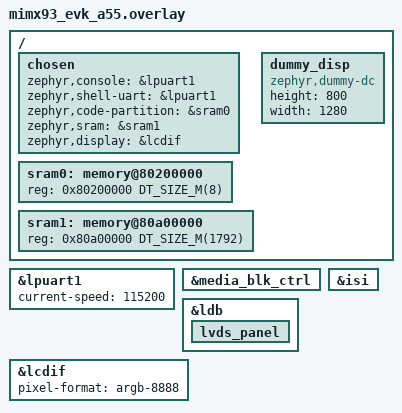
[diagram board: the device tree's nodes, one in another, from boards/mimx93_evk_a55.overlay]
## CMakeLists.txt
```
# Copyright 2024, NXP
# SPDX-License-Identifier: Apache-2.0

cmake_minimum_required(VERSION 3.20.0)

set(SHIELD nxp_x_rpi_cam_int)
find_package(Zephyr REQUIRED HINTS $ENV{ZEPHYR_BASE})

project(barcode_scanner)

# include directories for headers
set (ZXING_HEADERS_DIR
  "src/zxing-cpp/core/src"
#  "src/zxing-cpp/core/src/oned"
#  "src/zxing-cpp/core/src/qrcode"
)

# build readers
#  set (ZXING_HEADERS_DIR ${ZXING_HEADERS_DIR}
#      src/zxing-cpp/core/src/qrcode/
#  )

# build writers
#  set (ZXING_HEADERS_DIR ${ZXING_HEADERS_DIR}
#      src/zxing-cpp/core/src/BitMatrix.h
#      src/zxing-cpp/core/src/BitMatrixIO.h
#      src/zxing-cpp/core/src/Matrix.h
#      src/zxing-cpp/core/src/MultiFormatWriter.h
#      src/zxing-cpp/core/src/Range.h
#  )

# end of public header set

set (ZXING_SOURCES
  # base
  "src/zxing-cpp/core/src/BarcodeFormat.cpp"
  "src/zxing-cpp/core/src/BitArray.cpp"
  "src/zxing-cpp/core/src/BitMatrix.cpp"
  "src/zxing-cpp/core/src/BitMatrixIO.cpp"
  "src/zxing-cpp/core/src/CharacterSet.cpp"
  "src/zxing-cpp/core/src/ConcentricFinder.cpp"
  "src/zxing-cpp/core/src/ECI.cpp"
  "src/zxing-cpp/core/src/GenericGF.cpp"
  "src/zxing-cpp/core/src/GenericGFPoly.cpp"
  "src/zxing-cpp/core/src/GTIN.cpp"
  "src/zxing-cpp/core/src/Utf.cpp"
  "src/zxing-cpp/core/src/ZXBigInteger.cpp"

  #libzueci
  "src/zxing-cpp/core/src/libzueci/zueci.c"

  #aztec common
  # no such files

  # datamatrix common
  "src/zxing-cpp/core/src/datamatrix/DMBitLayout.cpp"
  "src/zxing-cpp/core/src/datamatrix/DMVersion.cpp"

  #oned commmon
  "src/zxing-cpp/core/src/oned/ODUPCEANCommon.cpp"
  "src/zxing-cpp/core/src/oned/ODCode128Patterns.cpp"

  #qr-code common
  "src/zxing-cpp/core/src/qrcode/QRCodecMode.cpp"
  "src/zxing-cpp/core/src/qrcode/QRErrorCorrectionLevel.cpp"
  "src/zxing-cpp/core/src/qrcode/QRVersion.cpp"
)
#zephyr_linker_sources(SECTIONS linker_chre.ld)

# build readers
  zephyr_compile_definitions(ZXING_BUILD_READERS)
  set (ZXING_SOURCES ${ZXING_SOURCES}
    #reader
    "src/zxing-cpp/core/src/BinaryBitmap.cpp"
    "src/zxing-cpp/core/src/BitSource.cpp"
    "src/zxing-cpp/core/src/Content.cpp"
    "src/zxing-cpp/core/src/DecodeHints.cpp"
    "src/zxing-cpp/core/src/GlobalHistogramBinarizer.cpp"
    "src/zxing-cpp/core/src/GridSampler.cpp"
    "src/zxing-cpp/core/src/HRI.cpp"
    "src/zxing-cpp/core/src/HybridBinarizer.cpp"
    "src/zxing-cpp/core/src/MultiFormatReader.cpp"
    "src/zxing-cpp/core/src/PerspectiveTransform.cpp"
    "src/zxing-cpp/core/src/ReadBarcode.cpp"
    "src/zxing-cpp/core/src/ReedSolomonDecoder.cpp"
    "src/zxing-cpp/core/src/Result.cpp"
    "src/zxing-cpp/core/src/ResultPoint.cpp"
    "src/zxing-cpp/core/src/TextDecoder.cpp"
    "src/zxing-cpp/core/src/WhiteRectDetector.cpp"

    #aztec reader
    "src/zxing-cpp/core/src/aztec/AZDecoder.cpp"
    "src/zxing-cpp/core/src/aztec/AZDetector.cpp"
    "src/zxing-cpp/core/src/aztec/AZReader.cpp"

    #datamatrix reader
    "src/zxing-cpp/core/src/datamatrix/DMDataBlock.cpp"
    "src/zxing-cpp/core/src/datamatrix/DMDecoder.cpp"
    "src/zxing-cpp/core/src/datamatrix/DMDetector.cpp"
    "src/zxing-cpp/core/src/datamatrix/DMReader.cpp"

    #maxicode reader
    "src/zxing-cpp/core/src/maxicode/MCBitMatrixParser.cpp"
    "src/zxing-cpp/core/src/maxicode/MCDecoder.cpp"
    "src/zxing-cpp/core/src/maxicode/MCReader.cpp"

    #oned reader
    "src/zxing-cpp/core/src/oned/ODCodabarReader.cpp"
    "src/zxing-cpp/core/src/oned/ODCode39Reader.cpp"
    "src/zxing-cpp/core/src/oned/ODCode93Reader.cpp"
    "src/zxing-cpp/core/src/oned/ODCode128Reader.cpp"
    "src/zxing-cpp/core/src/oned/ODDataBarCommon.cpp"
    "src/zxing-cpp/core/src/oned/ODDataBarReader.cpp"
    "src/zxing-cpp/core/src/oned/ODDataBarExpandedBitDecoder.cpp"
    "src/zxing-cpp/core/src/oned/ODDataBarExpandedReader.cpp"
    "src/zxing-cpp/core/src/oned/ODITFReader.cpp"
    "src/zxing-cpp/core/src/oned/ODMultiUPCEANReader.cpp"
    "src/zxing-cpp/core/src/oned/ODReader.cpp"
    "src/zxing-cpp/core/src/oned/ODRowReader.cpp"

    #pdf417 reader
    "src/zxing-cpp/core/src/pdf417/PDFBarcodeValue.cpp"
    "src/zxing-cpp/core/src/pdf417/PDFBoundingBox.cpp"
    "src/zxing-cpp/core/src/pdf417/PDFCodewordDecoder.cpp"
    "src/zxing-cpp/core/src/pdf417/PDFDecoder.cpp"
    "src/zxing-cpp/core/src/pdf417/PDFDetectionResult.cpp"
    "src/zxing-cpp/core/src/pdf417/PDFDetectionResultColumn.cpp"
    "src/zxing-cpp/core/src/pdf417/PDFDetector.cpp"
    "src/zxing-cpp/core/src/pdf417/PDFModulusGF.cpp"
    "src/zxing-cpp/core/src/pdf417/PDFModulusPoly.cpp"
    "src/zxing-cpp/core/src/pdf417/PDFReader.cpp"
    "src/zxing-cpp/core/src/pdf417/PDFScanningDecoder.cpp"

    #qr-code reader
    "src/zxing-cpp/core/src/qrcode/QRBitMatrixParser.cpp"
    "src/zxing-cpp/core/src/qrcode/QRDataBlock.cpp"
    "src/zxing-cpp/core/src/qrcode/QRDecoder.cpp"
    "src/zxing-cpp/core/src/qrcode/QRDetector.cpp"
    "src/zxing-cpp/core/src/qrcode/QRFormatInformation.cpp"
    "src/zxing-cpp/core/src/qrcode/QRReader.cpp"
  )

# build writers
#  zephyr_compile_definitions(ZXING_BUILD_WRITERS)
#  set (ZXING_SOURCES ${ZXING_SOURCES}
#    #writer
#    "src/zxing-cpp/core/src/ReedSolomonEncoder.cpp"
#    "src/zxing-cpp/core/src/TextEncoder.cpp"
#    "src/zxing-cpp/core/src/MultiFormatWriter.cpp"
#
#    # oned writer
#    "src/zxing-cpp/core/src/oned/ODCodabarWriter.cpp"
#    "src/zxing-cpp/core/src/oned/ODCode39Writer.cpp"
#    "src/zxing-cpp/core/src/oned/ODCode93Writer.cpp"
#    "src/zxing-cpp/core/src/oned/ODCode128Writer.cpp"
#    "src/zxing-cpp/core/src/oned/ODEAN8Writer.cpp"
#    "src/zxing-cpp/core/src/oned/ODEAN13Writer.cpp"
#    "src/zxing-cpp/core/src/oned/ODITFWriter.cpp"
#    "src/zxing-cpp/core/src/oned/ODUPCEWriter.cpp"
#    "src/zxing-cpp/core/src/oned/ODUPCAWriter.cpp"
#    "src/zxing-cpp/core/src/oned/ODWriterHelper.cpp"
#
#    #qr-code writer
#    "src/zxing-cpp/core/src/qrcode/QREncoder.cpp"
#    "src/zxing-cpp/core/src/qrcode/QRMaskUtil.cpp"
#    "src/zxing-cpp/core/src/qrcode/QRMatrixUtil.cpp"
#    "src/zxing-cpp/core/src/qrcode/QRWriter.cpp"
#  )

target_include_directories(app PRIVATE
    ${ZXING_HEADERS_DIR}
    src/generated
    src/custom
    src/generated/guider_customer_fonts
    src/generated/guider_fonts
    src/generated/images
)

target_compile_definitions(app PRIVATE Zxing_EXPORTS)

FILE(GLOB gui_guider_sources src/*.c src/generated/*.c src/custom/*.c src/generated/guider_customer_fonts/*.c src/generated/guider_fonts/*.c src/generated/images/*.c)

target_sources(app PRIVATE
    ${ZXING_SOURCES}
    ${gui_guider_sources}
    src/main.cpp
    src/zx_scan.cpp
)

target_compile_definitions(app PRIVATE LV_LVGL_H_INCLUDE_SIMPLE)
```

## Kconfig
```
# Copyright 2024, NXP
# SPDX-License-Identifier: Apache-2.0

menu "Barcode scanner demo"

config BARCODE_TIME_MEASUREMENT
	bool "measure main thread execution time"
	default n
	help
	  measure main thread execution time

config BARCODE_VIDEO_FRAME_CHECK
	bool "check for empty video frame"
	default n
	help
	  check for empty video frame

module = BARCODE_MAIN
module-str = barcode scanner main thread
source "subsys/logging/Kconfig.template.log_config"

module = BARCODE_ZXING
module-str = barcode scanner zxing thread
source "subsys/logging/Kconfig.template.log_config"

endmenu

source "Kconfig.zephyr"
```

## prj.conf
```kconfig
# Copyright 2024,2025 NXP
# SPDX-License-Identifier: Apache-2.0

## DEVICE ##
CONFIG_SERIAL=y
CONFIG_UART_INTERRUPT_DRIVEN=y
CONFIG_DISPLAY=y
CONFIG_VIDEO=y
CONFIG_VIDEO_BUFFER_POOL_NUM_MAX=5

## KERNEL ##
CONFIG_SPEED_OPTIMIZATIONS=y
CONFIG_SCHED_SCALABLE=y
CONFIG_WAITQ_SCALABLE=y
CONFIG_PICOLIBC=y
# CONFIG_PICOLIBC_USE_MODULE is not set
CONFIG_MAIN_STACK_SIZE=16384
CONFIG_SYSTEM_WORKQUEUE_STACK_SIZE=16384
#CONFIG_HEAP_MEM_POOL_SIZE=4194304
CONFIG_COMMON_LIBC_MALLOC_ARENA_SIZE=16777216

## SHELL ##
CONFIG_CONSOLE=y
CONFIG_UART_CONSOLE=y
CONFIG_LOG=y
CONFIG_LOG_RUNTIME_FILTERING=y
CONFIG_LOG_PRINTK=y
CONFIG_LOG_DEFAULT_LEVEL=2
CONFIG_LOG_SPEED=y
CONFIG_LOG_BLOCK_IN_THREAD=y
CONFIG_LOG_BLOCK_IN_THREAD_TIMEOUT_MS=16
CONFIG_LOG_BUFFER_SIZE=16384
CONFIG_SHELL=y
CONFIG_SHELL_PROMPT_UART="zephyr:~$ "
CONFIG_SHELL_BACKEND_SERIAL_LOG_MESSAGE_QUEUE_TIMEOUT=1000
CONFIG_SHELL_BACKEND_SERIAL_LOG_MESSAGE_QUEUE_SIZE=4096

## STATS ##
CONFIG_STATS=y
CONFIG_THREAD_RUNTIME_STATS=y
CONFIG_THREAD_RUNTIME_STATS_USE_TIMING_FUNCTIONS=y

## CPP ##
CONFIG_CPP=y
CONFIG_STD_CPP17=y
CONFIG_GLIBCXX_LIBCPP=y
CONFIG_CPP_EXCEPTIONS=y
CONFIG_CPP_RTTI=y

## LVGL ##
CONFIG_LV_Z_MEM_POOL_HEAP_LIB_C=y
CONFIG_LVGL=y
CONFIG_LV_Z_SHELL=y
CONFIG_LV_USE_LOG=y
CONFIG_LV_USE_KEYBOARD=n

## APP ##
CONFIG_BARCODE_TIME_MEASUREMENT=n
CONFIG_BARCODE_VIDEO_FRAME_CHECK=n
CONFIG_BARCODE_MAIN_LOG_LEVEL_WRN=y
CONFIG_BARCODE_ZXING_LOG_LEVEL_WRN=y
```

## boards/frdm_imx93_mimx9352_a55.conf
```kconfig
# Copyright 2024,2025 NXP
# SPDX-License-Identifier: Apache-2.0

## DEVICE ##
CONFIG_PINCTRL=y
CONFIG_PINCTRL_DYNAMIC=y
CONFIG_CLOCK_CONTROL=y
CONFIG_GPIO=y
CONFIG_GPIO_SHELL=y
CONFIG_PM_CPU_OPS=y
CONFIG_PSCI_SHELL=y
CONFIG_REGULATOR=y
CONFIG_REGULATOR_FIXED=y
CONFIG_I2C=y
CONFIG_I2C_CALLBACK=y
CONFIG_MFD_ADP5585_INIT_PRIORITY=55
CONFIG_GPIO_ADP5585_INIT_PRIORITY=56
CONFIG_GPIO_PCA_SERIES_INIT_PRIORITY=60
CONFIG_REGULATOR_FIXED_INIT_PRIORITY=75
CONFIG_VIDEO_MCUX_ISI_INIT_PRIORITY=90
CONFIG_DISPLAY_INIT_PRIORITY=85
CONFIG_VIDEO_INIT_PRIORITY=90

## STATS ##
CONFIG_I2C_STATS=y

## KERNEL ##
#CONFIG_XIP=y
#CONFIG_USE_DT_CODE_PARTITION=y
#CONFIG_KERNEL_VM_SIZE=0x80000000
#CONFIG_MAX_XLAT_TABLES=256
CONFIG_VIDEO_BUFFER_POOL_SZ_MAX=2097152

## LVGL ##
CONFIG_LV_COLOR_DEPTH_32=y
CONFIG_LV_Z_DOUBLE_VDB=y
CONFIG_LV_Z_VDB_SIZE=100
CONFIG_LV_Z_FULL_REFRESH=y
```

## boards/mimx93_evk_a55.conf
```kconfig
# Copyright 2024, NXP
# SPDX-License-Identifier: Apache-2.0

## DEVICE ##
CONFIG_PINCTRL=y
CONFIG_PINCTRL_DYNAMIC=y
CONFIG_CLOCK_CONTROL=y
CONFIG_GPIO=y
CONFIG_GPIO_SHELL=y
CONFIG_REGULATOR=y
CONFIG_REGULATOR_FIXED=y
CONFIG_SERIAL=y
CONFIG_UART_INTERRUPT_DRIVEN=y
CONFIG_I2C=y
CONFIG_I2C_CALLBACK=y
CONFIG_DISPLAY=y
CONFIG_VIDEO=y
CONFIG_VIDEO_BUFFER_POOL_SZ_MAX=8192000
CONFIG_VIDEO_BUFFER_POOL_NUM_MAX=5
CONFIG_GPIO_INIT_PRIORITY=10
CONFIG_I2C_INIT_PRIORITY=15
CONFIG_GPIO_ADP5585_GPIO_INIT_PRIORITY=20
CONFIG_GPIO_PCA953X_INIT_PRIORITY=21
CONFIG_GPIO_HOGS_INIT_PRIORITY=25
CONFIG_REGULATOR_FIXED_INIT_PRIORITY=30
CONFIG_VIDEO_MT9M114_INIT_PRIORITY=70
CONFIG_VIDEO_PARALLEL_CSI_INIT_PRIORITY=80
CONFIG_DISPLAY_INIT_PRIORITY=85
CONFIG_VIDEO_INIT_PRIORITY=90

## KERNEL ##
CONFIG_XIP=y
CONFIG_USE_DT_CODE_PARTITION=y

CONFIG_KERNEL_VM_SIZE=0x80000000
CONFIG_COMMON_LIBC_MALLOC_ARENA_SIZE=268435456

CONFIG_MAX_XLAT_TABLES=256
```

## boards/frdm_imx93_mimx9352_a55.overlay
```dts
/*
 * Copyright 2024,2025 NXP
 *
 * SPDX-License-Identifier: Apache-2.0
 */

/delete-node/ &dram;

/{
	chosen{
		zephyr,console = &lpuart1;
		zephyr,shell-uart = &lpuart1;
	};

	dram: memory@d0000000 {
		reg = <0xd0000000 DT_SIZE_M(512)>;
	};
};

&lpuart1 {
	current-speed = <115200>;
	status = "okay";
};
```

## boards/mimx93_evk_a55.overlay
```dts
/*
 * Copyright 2024, NXP
 *
 * SPDX-License-Identifier: Apache-2.0
 */

/delete-node/ &sram0;

/{
	chosen{
		zephyr,console = &lpuart1;
		zephyr,shell-uart = &lpuart1;
		zephyr,code-partition = &sram0;
		zephyr,sram = &sram1;
		zephyr,display = &lcdif;
	};

	sram0: memory@80200000 {
		reg = <0x80200000 DT_SIZE_M(8)>;
	};

	sram1: memory@80a00000 {
		reg = <0x80a00000 DT_SIZE_M(1792)>;
	};

	dummy_disp: dummy_disp {
		compatible = "zephyr,dummy-dc";
		height = <800>;
		width = <1280>;
		status = "okay";
	};
};

&lpuart1 {
	current-speed = <115200>;
};

&media_blk_ctrl {
	status = "okay";
};

&ldb {
	status = "okay";

	lvds_panel: lvds_panel {
		status = "okay";
	};
};

&lcdif {
	pixel-format = "argb-8888";
	status = "okay";
};

&isi {
	status = "okay";
};
```

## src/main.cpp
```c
/*
 * Copyright 2024,2025 NXP
 *
 * SPDX-License-Identifier: Apache-2.0
 */
/** ZephyrOS include group */
#include <zephyr/cache.h>
#include <zephyr/device.h>
#include <zephyr/drivers/display.h>
#include <zephyr/drivers/i2c.h>
#include <zephyr/drivers/video.h>
#include <zephyr/kernel.h>
#include <zephyr/sys/printk.h>
#include <zephyr/sys/util.h>

/** C STD include group */
#include <cinttypes>
#include <cstdio>
#include <cstring>

/** CPP STD/STL include group */
#include <vector>

/** GUI-Guider include group */
#include "../custom/custom.h"
#include "../generated/events_init.h"
#include "../generated/gui_guider.h"

/** Project include group */
#include "zx_scan.h"

/** Zephyr logging include group */
#include <zephyr/logging/log.h>
LOG_MODULE_REGISTER(main_tr, CONFIG_BARCODE_MAIN_LOG_LEVEL);

const struct device *video_dev = DEVICE_DT_GET(DT_CHOSEN(zephyr_camera));
struct video_buffer *my_video_buffer_pool[CONFIG_VIDEO_BUFFER_POOL_NUM_MAX];

const struct device *display_dev = DEVICE_DT_GET(DT_CHOSEN(zephyr_display));

K_THREAD_STACK_DEFINE(zx_scan_thread_stack, ZX_SCAN_THREAD_STACK_SIZE);
struct k_thread zx_scan_thread;
zx_scan_param_t zx_param =
{
    .prio_normal = ZX_SCAN_THREAD_NORMAL_PRIO,
    .width = 640,
    .height = 600,
};
zx_scan_t zx_scan;

lv_ui guider_ui;

lv_image_dsc_t img_preview_desc = {
    .header = {
        .magic = LV_IMAGE_HEADER_MAGIC,
        .cf = LV_COLOR_FORMAT_ARGB8888,
        .flags = 0,
        .w = 640,
        .h = 600,
        .stride = 640 * 4,
        .reserved_2 = 0,
    },
  .data_size = 640 * 600 * 4,
  .data = nullptr,
};

#ifdef CONFIG_BARCODE_TIME_MEASUREMENT
/** used by time measurement */
uint64_t stime, etime;
#endif // CONFIG_BARCODE_TIME_MEASUREMENT

int disp_dev_config(struct device const * const dev, struct display_buffer_descriptor *desc)
{
    struct display_capabilities capabilities;
    int ret = 0;

    if (!device_is_ready(dev)) {
        LOG_ERR("Display device %s not ready", dev->name);
        return -ENODEV;
    }

    LOG_INF("Configuring display: %s", dev->name);

    // Retrieve display capabilities
    display_get_capabilities(dev, &capabilities);

    LOG_INF("- Capabilities:");
    LOG_INF("  Resolution: %u x %u", capabilities.x_resolution, capabilities.y_resolution);
    LOG_INF("  Supported formats: 0x%08x, Current format: %u", 
            capabilities.supported_pixel_formats, capabilities.current_pixel_format);
    LOG_INF("  Current orientation: %u", capabilities.current_orientation);

    // Verify resolution support
    if (capabilities.x_resolution != 1024 || capabilities.y_resolution != 600) {
        LOG_ERR("Unsupported resolution: %u x %u (expected: 1024 x 600)", 
                capabilities.x_resolution, capabilities.y_resolution);
        return -EINVAL;
    }

    // Set pixel format to ARGB8888
    ret = display_set_pixel_format(dev, PIXEL_FORMAT_ARGB_8888);
    if (ret) {
        LOG_ERR("Failed to set pixel format");
        return ret;
    }

    // Define buffer dimensions (fixed for this display)
    const size_t rect_w = 1024;
    const size_t rect_h = 600;

    // Calculate buffer size and pitch
    const size_t buf_size = rect_w * rect_h * 4;  // 4 bytes per pixel (ARGB8888)
    const size_t pitch = rect_w * 4;

    LOG_INF("Buffer: %zu x %zu, size=%zu bytes, pitch=%zu bytes", 
            rect_w, rect_h, buf_size, pitch);

    // Populate descriptor
    desc->buf_size = buf_size;
    desc->pitch = pitch;
    desc->width = rect_w;
    desc->height = rect_h;

    return 0;
}

/**
 * @brief Configures the video device (camera) with desired format, frame rate, and capabilities.
 *
 * This function:
 * - Queries and logs input/output capabilities.
 * - Sets input (camera) format to UYVY (640x600).
 * - Sets output format to AR24 (640x600).
 * - Sets frame rate to 30 fps.
 * - Enumerates supported frame intervals.
 *
 * @param dev Pointer to the video device.
 * @param fmt Pointer to output format structure to be filled.
 * @return 0 on success, non-zero on failure.
 */
int video_dev_config(const struct device *const dev, struct video_format *const fmt)
{
    struct video_caps caps;
    struct video_format output_fmt;
#if CONFIG_DT_HAS_NXP_IMX_ISI_ENABLED
    struct video_format camera_fmt;
#endif // CONFIG_DT_HAS_NXP_IMX_ISI_ENABLED
    struct video_frmival frmival;
    struct video_frmival_enum fie;
    int i = 0;

    if (!device_is_ready(dev)) {
        LOG_ERR("Video device %s not ready", dev->name);
        return -ENODEV;
    }

#if CONFIG_DT_HAS_NXP_IMX_ISI_ENABLED
    /* Query input endpoint (camera) capabilities */
    if (video_get_caps(dev, VIDEO_EP_IN, &caps)) {
        LOG_ERR("Failed to retrieve input capabilities");
        return -EIO;
    }

    LOG_INF("- Input Capabilities:");
    while (caps.format_caps[i].pixelformat) {
        const struct video_format_cap *fcap = &caps.format_caps[i];
        LOG_INF("  %c%c%c%c | W[%u;%u;%u] | H[%u;%u;%u]",
               (char)fcap->pixelformat,
               (char)(fcap->pixelformat >> 8),
               (char)(fcap->pixelformat >> 16),
               (char)(fcap->pixelformat >> 24),
               fcap->width_min, fcap->width_max, fcap->width_step,
               fcap->height_min, fcap->height_max, fcap->height_step);
        i++;
    }
    i = 0;
#endif // CONFIG_DT_HAS_NXP_IMX_ISI_ENABLED

    /* Query output endpoint (processing) capabilities */
    if (video_get_caps(dev, VIDEO_EP_OUT, &caps)) {
        LOG_ERR("Failed to retrieve output capabilities");
        return -EIO;
    }

    LOG_INF("- Output Capabilities:");
    while (caps.format_caps[i].pixelformat) {
        const struct video_format_cap *fcap = &caps.format_caps[i];
        LOG_INF("  %c%c%c%c | W[%u;%u;%u] | H[%u;%u;%u]",
               (char)fcap->pixelformat,
               (char)(fcap->pixelformat >> 8),
               (char)(fcap->pixelformat >> 16),
               (char)(fcap->pixelformat >> 24),
               fcap->width_min, fcap->width_max, fcap->width_step,
               fcap->height_min, fcap->height_max, fcap->height_step);
        i++;
    }

#if CONFIG_DT_HAS_NXP_IMX_ISI_ENABLED
    /* Configure input (camera) format: UYVY, 640x600 */
    if (video_get_format(dev, VIDEO_EP_IN, &camera_fmt)) {
        LOG_ERR("Failed to retrieve default input format");
        return -EIO;
    }

    camera_fmt.pixelformat = VIDEO_FOURCC_FROM_STR("UYVY");
    camera_fmt.width = 640;
    camera_fmt.height = 600;
    camera_fmt.pitch = fmt->width * video_bits_per_pixel(fmt->pixelformat) / BITS_PER_BYTE;

    LOG_INF("- Input Format: %c%c%c%c @ %ux%u",
           (char)camera_fmt.pixelformat,
           (char)(camera_fmt.pixelformat >> 8),
           (char)(camera_fmt.pixelformat >> 16),
           (char)(camera_fmt.pixelformat >> 24),
           camera_fmt.width, camera_fmt.height);

    if (video_set_format(dev, VIDEO_EP_IN, &camera_fmt)) {
        LOG_ERR("Failed to set input format");
        return -EIO;
    }
#endif // CONFIG_DT_HAS_NXP_IMX_ISI_ENABLED

    /* Configure output format: AR24, 640x600 */
    if (video_get_format(dev, VIDEO_EP_OUT, &output_fmt)) {
        LOG_ERR("Failed to retrieve default output format");
        return -EIO;
    }

    output_fmt.pixelformat = VIDEO_FOURCC_FROM_STR("AR24");
    output_fmt.width = 640;
    output_fmt.height = 600;
    output_fmt.pitch = output_fmt.width * video_bits_per_pixel(output_fmt.pixelformat) / BITS_PER_BYTE;

    LOG_INF("- Output Format: %c%c%c%c @ %ux%u",
           (char)output_fmt.pixelformat,
           (char)(output_fmt.pixelformat >> 8),
           (char)(output_fmt.pixelformat >> 16),
           (char)(output_fmt.pixelformat >> 24),
           output_fmt.width, output_fmt.height);

    if (video_set_format(dev, VIDEO_EP_OUT, &output_fmt)) {
        LOG_ERR("Failed to set output format");
        return -EIO;
    }

    /* Copy final format to output */
    memcpy(fmt, &output_fmt, sizeof(struct video_format));

    /* Query and log default frame rate */
    if (!video_get_frmival(dev, VIDEO_EP_OUT, &frmival)) {
        LOG_INF("- Default frame rate: %.2f fps",
               1.0 * frmival.denominator / frmival.numerator);
    }

    /* List supported frame intervals for the output format */
    LOG_INF("- Supported frame intervals:");
    memset(&fie, 0, sizeof(fie));
#if CONFIG_DT_HAS_NXP_IMX_ISI_ENABLED
    fie.format = &camera_fmt;
#else // CONFIG_DT_HAS_NXP_IMX_ISI_ENABLED
    fie.format = &output_fmt;  // Fixed typo: 'outout_fmt' → 'output_fmt'
#endif // CONFIG_DT_HAS_NXP_IMX_ISI_ENABLED

    while (1) {
        int ret = video_enum_frmival(dev, VIDEO_EP_OUT, &fie);
        if (ret) {
            break;
        }

        LOG_INF("  Index %u: ret=%d", fie.index, ret);
        if (fie.type == VIDEO_FRMIVAL_TYPE_DISCRETE) {
            LOG_INF("    %u/%u", fie.discrete.numerator, fie.discrete.denominator);
        } else {
            LOG_INF("    [min=%u/%u; max=%u/%u; step=%u/%u]",
                   fie.stepwise.min.numerator, fie.stepwise.min.denominator,
                   fie.stepwise.max.numerator, fie.stepwise.max.denominator,
                   fie.stepwise.step.numerator, fie.stepwise.step.denominator);
        }
        fie.index++;
    }

    /* Set frame rate to 30 fps */
    frmival.numerator = 30;
    frmival.denominator = 1;

    if (!video_set_frmival(dev, VIDEO_EP_OUT, &frmival)) {
        LOG_INF("- Frame rate set to %.2f fps", 1.0 * frmival.denominator / frmival.numerator);
    } else {
        LOG_ERR("- Failed to set frame rate to %.2f fps", 1.0 * frmival.denominator / frmival.numerator);
        return -EIO;
    }

    LOG_INF("Video device configuration completed successfully");
    return 0;
}

/**
 * @brief Main application entry point.
 *
 * Initializes:
 * - Video and display devices
 * - Video buffer pool
 * - ZXing scan thread
 * - GUI
 * - Starts video stream
 * - Main loop: dequeue, process, display, enqueue
 */
int main(void)
{
    struct display_buffer_descriptor buf_desc;
    struct video_format fmt_desc;
    volatile bool zx_frame_copied = false;
    int frame_cnt = 0;
    struct video_buffer *vbuf = nullptr;

    // Set thread priority
    k_thread_priority_set(k_current_get(), 5);

    // Configure video device
    if (video_dev_config(video_dev, &fmt_desc) != 0) {
        LOG_ERR("Failed to configure video device");
        return -1;
    }

    int bsize = fmt_desc.pitch * fmt_desc.height;
    LOG_INF("Buffer size: %ld, Pool size: %ld", bsize, ARRAY_SIZE(my_video_buffer_pool));

    // Allocate and enqueue video buffers
    for (int i = 0; i < ARRAY_SIZE(my_video_buffer_pool); i++) {
        my_video_buffer_pool[i] = video_buffer_aligned_alloc(bsize, CONFIG_VIDEO_BUFFER_POOL_ALIGN, K_FOREVER);
        if (!my_video_buffer_pool[i]) {
            LOG_ERR("Failed to allocate video buffer %d", i);
            return -1;
        }

#ifdef CONFIG_BARCODE_VIDEO_FRAME_CHECK
        ((uint32_t*)my_video_buffer_pool[i]->buffer)[0] = 0x00f0f0f0;
#endif // CONFIG_BARCODE_VIDEO_FRAME_CHECK

        if (video_enqueue(video_dev, VIDEO_EP_OUT, my_video_buffer_pool[i])) {
            LOG_ERR("Failed to enqueue buffer %d", i);
            return -1;
        }

        LOG_INF("Buffer %d/%d: 0x%8.8p", i, ARRAY_SIZE(my_video_buffer_pool), (void*)my_video_buffer_pool[i]->buffer);
    }

    // Configure display
    if (disp_dev_config(display_dev, &buf_desc) != 0) {
        LOG_ERR("Failed to configure display");
        return -1;
    }

    // Start ZXing scan thread
    k_thread_create(&zx_scan_thread, zx_scan_thread_stack,
                    ZX_SCAN_THREAD_STACK_SIZE,
                    (k_thread_entry_t)ZX_ScanTask, (void*)&zx_scan, (void*)&zx_param, NULL,
                    ZX_SCAN_THREAD_START_PRIO, 0, K_NO_WAIT);
    k_yield();

    // Initialize GUI
    setup_ui(&guider_ui);
    events_init(&guider_ui);
    lv_img_set_src(guider_ui.scanner_image_camera_preview, &img_preview_desc);

#ifdef CONFIG_BARCODE_TIME_MEASUREMENT
    etime = k_cyc_to_us_near64(k_cycle_get_64());
    LOG_WRN("Boot time: %lld us", etime);
#endif // CONFIG_BARCODE_TIME_MEASUREMENT

    // Start video capture
    if (video_stream_start(video_dev)) {
        LOG_ERR("Failed to start video stream");
        return -1;
    }
    LOG_INF("Video stream started");

    // Main processing loop
    while (true) {
        if (video_dequeue(video_dev, VIDEO_EP_OUT, &vbuf, K_FOREVER)) {
            LOG_ERR("Failed to dequeue video buffer");
            break;
        }

#ifdef CONFIG_BARCODE_VIDEO_FRAME_CHECK
        if (((uint32_t*)vbuf->buffer)[0] == 0x00f0f0f0) {
            LOG_WRN("Invalid frame detected, skipping");
            video_enqueue(video_dev, VIDEO_EP_OUT, vbuf);
            continue;
        }
#endif // CONFIG_BARCODE_VIDEO_FRAME_CHECK

#ifdef CONFIG_BARCODE_TIME_MEASUREMENT
        stime = k_cyc_to_us_near64(k_cycle_get_64());
#endif // CONFIG_BARCODE_TIME_MEASUREMENT

        LOG_DBG("Processing frame %d", frame_cnt);

        // Process ZXing results if available
        if (zx_frame_copied && k_mutex_lock(&zx_scan.lock, K_NO_WAIT) == 0) {
            zx_frame_copied = false;
            lv_label_set_text(guider_ui.scanner_text_results, zx_scan.results_str);
            LOG_DBG("ZXing results: %s", zx_scan.results_str);
            k_mutex_unlock(&zx_scan.lock);
        }

        // Send frame to ZXing every 6th frame
        if ((frame_cnt % 6 == 0) && ZX_SendFrame(&zx_scan,
                frame_cnt, vbuf->buffer, vbuf->bytesused) == 0) {
            zx_frame_copied = true;
        }

        // Update preview image
        img_preview_desc.data = vbuf->buffer;
        lv_img_set_src(guider_ui.scanner_image_camera_preview, &img_preview_desc);
        update_scan_anim(&guider_ui);
        lv_refr_now(NULL);

        // Re-enqueue buffer after processing
        if (vbuf) {
#ifdef CONFIG_BARCODE_VIDEO_FRAME_CHECK
            ((uint32_t*)vbuf->buffer)[0] = 0x00f0f0f0;
#endif // CONFIG_BARCODE_VIDEO_FRAME_CHECK
            if (video_enqueue(video_dev, VIDEO_EP_OUT, vbuf)) {
                LOG_ERR("Failed to enqueue video buffer");
                break;
            }
        }

        // Final refresh
        lv_refr_now(NULL);

#ifdef CONFIG_BARCODE_TIME_MEASUREMENT
        etime = k_cyc_to_us_near64(k_cycle_get_64());
        LOG_WRN("ts: %lld us, loop time: %lld us", etime, etime - stime);
#endif // CONFIG_BARCODE_TIME_MEASUREMENT

        LOG_INF("Frame %d processed", frame_cnt);
        ++frame_cnt;
    }

    // Stop video stream
    if (video_stream_stop(video_dev)) {
        LOG_ERR("Failed to stop video stream");
        return -1;
    }
    LOG_INF("Video stream stopped");

    return 0;
}
```

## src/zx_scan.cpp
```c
/*
 * Copyright 2024,2025 NXP
 *
 * SPDX-License-Identifier: Apache-2.0
 */
#include "zx_scan.h"

#include <iostream>
#include <sstream>
#include <string>
#include <functional>

#include <zephyr/logging/log.h>
LOG_MODULE_REGISTER(zx_scan, CONFIG_BARCODE_ZXING_LOG_LEVEL);

size_t ZX_ResultFormatString(char *const result_str, size_t str_len,
                             const ZXing::Result &result)
{
    size_t result_str_len = 0;

    // Format basic information
    result_str_len += snprintf(
        result_str + result_str_len, str_len - result_str_len,
        "  Text      : \"%s\"\n"
        "  Format    : %s\n"
        "  Identifier: %s\n"
        "  Position  : %3.3dx%3.3d %3.3dx%3.3d\n"
        "              %3.3dx%3.3d %3.3dx%3.3d\n"
        "  Rotation  : %d deg\n"
        "  EC Level  : %s\n"
        "  Version   : %s\n",
        std::string(result.bytes().asString()).c_str(),
        ZXing::ToString(result.format()).c_str(),
        result.symbologyIdentifier().c_str(),
        result.position().topLeft().x, result.position().topLeft().y,
        result.position().bottomLeft().x, result.position().bottomLeft().y,
        result.position().bottomRight().x, result.position().bottomRight().y,
        result.position().topRight().x, result.position().topRight().y,
        result.orientation(),
        result.ecLevel().empty() ? "N/A" : result.ecLevel().c_str(),
        result.version().empty() ? "N/A" : result.version().c_str()
    );

    return result_str_len;
}

int ZX_SendFrame(zx_scan_t *const scan, uint32_t frame_no, uint8_t *frame_buf,
                 size_t frame_size)
{
    if (k_mutex_lock(&scan->lock, K_NO_WAIT) == 0) {
        LOG_DBG("ZXing send frame %d", frame_no);
        scan->frame_no = frame_no;
        memcpy(scan->frame_buffer, frame_buf, frame_size);
        k_mutex_unlock(&scan->lock);
        k_condvar_signal(&scan->cond);
        return 0;
    } else {
        LOG_WRN("ZXing skip frame %d (busy)", frame_no);
        return -EBUSY;
    }
}

void ZX_ScanTask(zx_scan_t *const scan, const zx_scan_param_t *const param, void *)
{
    assert(scan);

#ifdef CONFIG_BARCODE_TIME_MEASUREMENT
    uint64_t stime, etime;
#endif

    LOG_INF("ZXing task starting");
    scan->thread_id = k_current_get();
    k_thread_name_set(scan->thread_id, "zx_scan");
    k_mutex_init(&scan->lock);
    k_condvar_init(&scan->cond);

    // Allocate frame buffer (RGBX, 4 bytes per pixel)
    size_t frame_size = param->width * param->height * 4;
    scan->frame_buffer = new (std::nothrow) uint8_t[frame_size];
    if (!scan->frame_buffer) {
        LOG_ERR("ZXing failed to allocate frame buffer");
        return;
    }

    // RAII guard for automatic cleanup
    std::unique_ptr<uint8_t[], std::function<void(uint8_t *)>> frame_alloc_guard(
        scan->frame_buffer, [](uint8_t *ptr) { delete[] ptr; }
    );

    // Allocate result string buffer
    scan->results_str = new (std::nothrow) char[ZX_SCAN_RESULTS_BUF_SIZE];
    if (!scan->results_str) {
        LOG_ERR("ZXing failed to allocate result string buffer");
        return;
    }

    // RAII guard for automatic cleanup
    std::unique_ptr<char[], std::function<void(char *)>> results_str_alloc_guard(
        scan->results_str, [](char *ptr) { delete[] ptr; }
    );

    // Initialize result string
    scan->results_str_len = 0;
    scan->preserve_old_result = true;
    scan->results_str_len += snprintf(
        scan->results_str + scan->results_str_len,
        ZX_SCAN_RESULTS_BUF_SIZE - scan->results_str_len,
        "No QR-Code detected yet.\n"
    );

    // Configure decoder hints
    ZXing::DecodeHints hints;
    hints.setTryHarder(true);
    hints.setTryRotate(true);
    hints.setTryInvert(false);
    hints.setTryDownscale(true);
    hints.setReturnErrors(false);
    hints.setFormats(ZXing::BarcodeFormat::MatrixCodes);
    hints.setTextMode(ZXing::TextMode::Plain);
    hints.setEanAddOnSymbol(ZXing::EanAddOnSymbol::Read);

    LOG_INF("ZXing task started successfully");
    k_thread_priority_set(k_current_get(), param->prio_normal);

    // Main loop
    while (true) {
        // Wait for new frame
        k_mutex_lock(&scan->lock, K_FOREVER);
        k_condvar_wait(&scan->cond, &scan->lock, K_FOREVER);

#ifdef CONFIG_BARCODE_TIME_MEASUREMENT
        stime = k_cyc_to_us_near64(k_cycle_get_64());
#endif // CONFIG_BARCODE_TIME_MEASUREMENT

        LOG_DBG("ZXing processing frame %d", scan->frame_no);

        // Create image view from frame buffer
        ZXing::ImageView qr_image(
            (const uint8_t *)scan->frame_buffer,
            param->width,
            param->height,
            ZXing::ImageFormat::RGBX
        );

        LOG_DBG("ZXing scanning (w: %d, h: %d)", param->width, param->height);

        // Perform barcode detection
        scan->results = ZXing::ReadBarcodes(qr_image, hints);

        // Format results
        if (scan->results.empty()) {
            if (!scan->preserve_old_result) {
                scan->preserve_old_result = true;
                scan->results_str_len += snprintf(
                    scan->results_str + scan->results_str_len,
                    ZX_SCAN_RESULTS_BUF_SIZE - scan->results_str_len,
                    "\nNo QR-Code found. Preserving last result.\n"
                );
            }
        } else {
            uint32_t result_no = 0;
            scan->results_str_len = 0;
            scan->preserve_old_result = false;

            // Header
            scan->results_str_len += snprintf(
                scan->results_str + scan->results_str_len,
                ZX_SCAN_RESULTS_BUF_SIZE - scan->results_str_len,
                "Scan result from frame %8.8d :\n",
                scan->frame_no
            );

            // Process up to MAX results
            for (auto&& result : scan->results) {
                scan->results_str_len += snprintf(
                    scan->results_str + scan->results_str_len,
                    ZX_SCAN_RESULTS_BUF_SIZE - scan->results_str_len,
                    "\nQR-Code NO.%d\n", result_no
                );

                scan->results_str_len += ZX_ResultFormatString(
                    scan->results_str + scan->results_str_len,
                    ZX_SCAN_RESULTS_BUF_SIZE - scan->results_str_len,
                    result
                );

                if (++result_no >= ZX_SCAN_RESULTS_NUM_MAX) {
                    break;
                }
            }

            // Final summary
            scan->results_str_len += snprintf(
                scan->results_str + scan->results_str_len,
                ZX_SCAN_RESULTS_BUF_SIZE - scan->results_str_len,
                "\nFound %d QR-Code(s)",
                scan->results.size()
            );

            if (scan->results.size() > ZX_SCAN_RESULTS_NUM_MAX) {
                scan->results_str_len += snprintf(
                    scan->results_str + scan->results_str_len,
                    ZX_SCAN_RESULTS_BUF_SIZE - scan->results_str_len,
                    ", %d result(s) omitted.\n",
                    scan->results.size() - ZX_SCAN_RESULTS_NUM_MAX
                );
            } else {
                scan->results_str_len += snprintf(
                    scan->results_str + scan->results_str_len,
                    ZX_SCAN_RESULTS_BUF_SIZE - scan->results_str_len,
                    ".\n"
                );
            }
        }

        // Null-terminate string
        scan->results_str[scan->results_str_len] = '\0';

#ifdef CONFIG_BARCODE_TIME_MEASUREMENT
        etime = k_cyc_to_us_near64(k_cycle_get_64());
        LOG_WRN("ZXing process frame %d took %lld us", scan->frame_no, etime - stime);
#endif // CONFIG_BARCODE_TIME_MEASUREMENT

        LOG_DBG("ZXing scan complete");

        k_mutex_unlock(&scan->lock);
    }
}
```

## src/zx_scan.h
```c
/*
 * Copyright 2024,2025 NXP
 *
 * SPDX-License-Identifier: Apache-2.0
 */
#ifndef ZX_SCAN_H
#define ZX_SCAN_H

#include <zephyr/kernel.h>
#include <zephyr/sys/printk.h>

/** C STD include group */
#include <cinttypes>
#include <cstring>
#include <cstdlib>
#include <cstdint>

/** CPP STD/STL include group */
#include <vector>

/** ZXing-CPP include group */
#include <BitMatrix.h>
#include <BitMatrixIO.h>
#include <DecodeHints.h>
#include <DecoderResult.h>
#include <ImageView.h>
#include <BinaryBitmap.h>
#include <qrcode/QRReader.h>
#include <qrcode/QRDecoder.h>
#include <MultiFormatReader.h>
#include <ReadBarcode.h>

#define ZX_SCAN_THREAD_START_PRIO (-1)
#define ZX_SCAN_THREAD_NORMAL_PRIO (8)
#define ZX_SCAN_THREAD_STACK_SIZE (0x10000)

#define ZX_SCAN_RESULTS_BUF_SIZE (16384)
#define ZX_SCAN_RESULTS_NUM_MAX (2)

typedef struct _zx_scan_param
{
    uint8_t prio_normal; /** specifies thread prio at normal run. */
    uint16_t width, height;
}zx_scan_param_t;

typedef struct _zx_scan
{
    struct k_mutex lock;
    struct k_condvar cond;
    k_tid_t thread_id;

    uint8_t *frame;
    uint32_t frame_no;

    ZXing::Results results;
    char *results_str;
    uint32_t results_str_len;
    bool preserve_old_result;
}zx_scan_t;

size_t ZX_ResultFormatString(char * const result_str, size_t str_len, ZXing::Result const & result);

int ZX_SendFrame(zx_scan_t *const scan, uint32_t frame_no, uint8_t *frame_buf, size_t frame_size);

void ZX_ScanTask(zx_scan_t *const scan, zx_scan_param_t const *const param, void*);

#endif // ZX_SCAN_H
```
